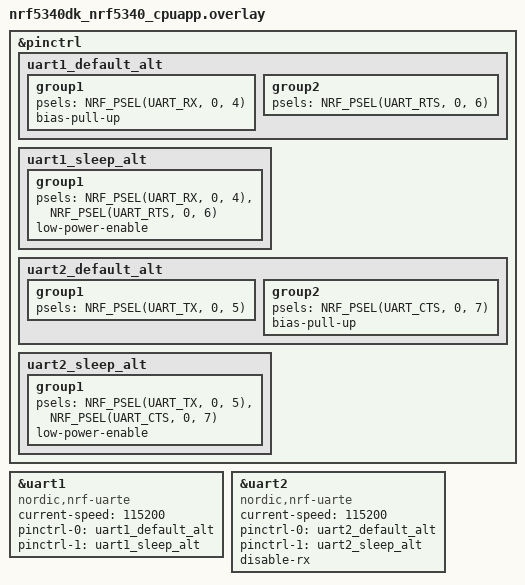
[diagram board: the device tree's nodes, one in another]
/* SPDX-License-Identifier: Apache-2.0 */

&pinctrl {
	uart1_default_alt: uart1_default_alt {
		group1 {
			psels = <NRF_PSEL(UART_RX, 0, 4)>;
			bias-pull-up;
		};
		group2 {
			psels = <NRF_PSEL(UART_RTS, 0, 6)>;
		};
	};

	uart1_sleep_alt: uart1_sleep_alt {
		group1 {
			psels = <NRF_PSEL(UART_RX, 0, 4)>,
				<NRF_PSEL(UART_RTS, 0, 6)>;
			low-power-enable;
		};
	};

	uart2_default_alt: uart2_default_alt {
		group1 {
			psels = <NRF_PSEL(UART_TX, 0, 5)>;
		};
		group2 {
			psels = <NRF_PSEL(UART_CTS, 0, 7)>;
			bias-pull-up;
		};
	};

	uart2_sleep_alt: uart2_sleep_alt {
		group1 {
			psels = <NRF_PSEL(UART_TX, 0, 5)>,
				<NRF_PSEL(UART_CTS, 0, 7)>;
			low-power-enable;
		};
	};
};

dut: &uart1 {
	current-speed = <115200>;
	compatible = "nordic,nrf-uarte";
	status = "okay";
	pinctrl-0 = <&uart1_default_alt>;
	pinctrl-1 = <&uart1_sleep_alt>;
	pinctrl-names = "default", "sleep";
};

dut_aux: &uart2 {
	current-speed = <115200>;
	compatible = "nordic,nrf-uarte";
	status = "okay";
	pinctrl-0 = <&uart2_default_alt>;
	pinctrl-1 = <&uart2_sleep_alt>;
	pinctrl-names = "default", "sleep";
	disable-rx;
};
